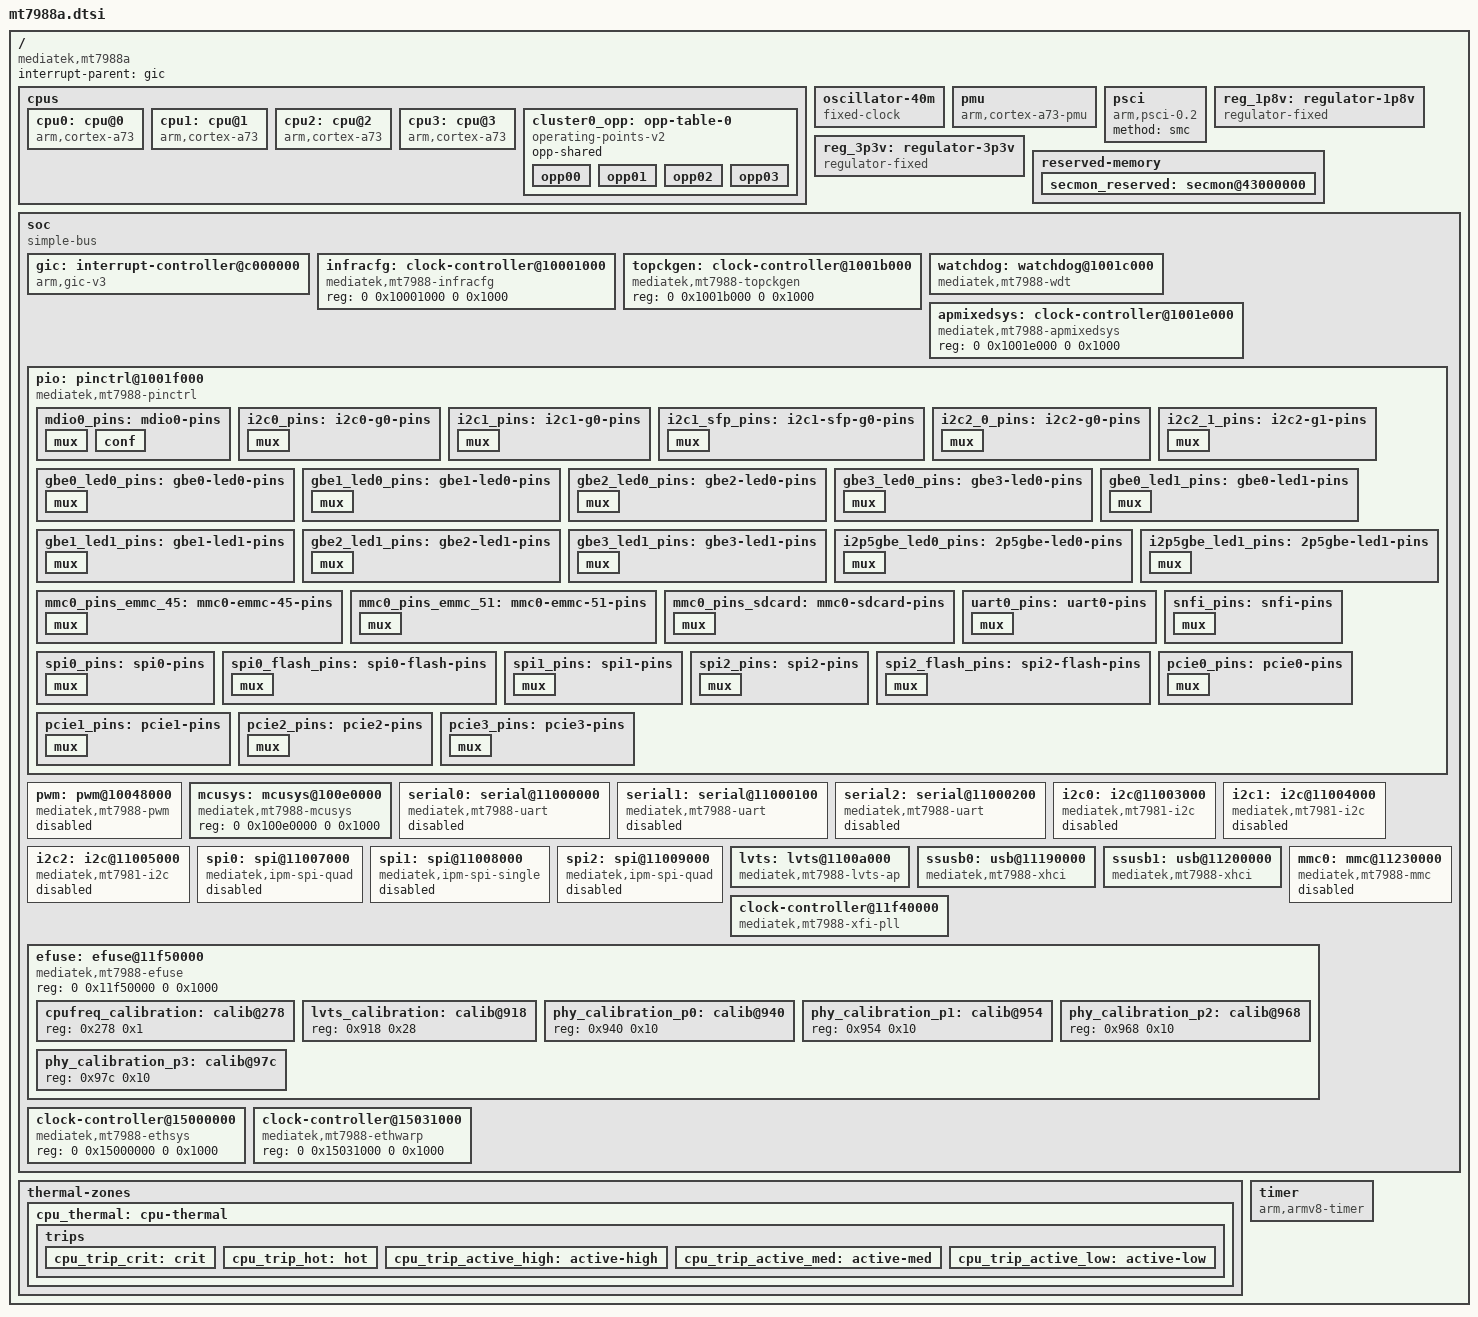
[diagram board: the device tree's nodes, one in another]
// SPDX-License-Identifier: GPL-2.0-only OR MIT

#include <dt-bindings/clock/mediatek,mt7988-clk.h>
#include <dt-bindings/interrupt-controller/arm-gic.h>
#include <dt-bindings/phy/phy.h>
#include <dt-bindings/pinctrl/mt65xx.h>
#include <dt-bindings/reset/mediatek,mt7988-resets.h>

/ {
	compatible = "mediatek,mt7988a";
	interrupt-parent = <&gic>;
	#address-cells = <2>;
	#size-cells = <2>;

	cpus {
		#address-cells = <1>;
		#size-cells = <0>;

		cpu0: cpu@0 {
			compatible = "arm,cortex-a73";
			reg = <0x0>;
			device_type = "cpu";
			enable-method = "psci";
			clocks = <&mcusys CLK_MCU_ARM_DIV_SEL>,
				 <&topckgen CLK_TOP_XTAL>;
			clock-names = "cpu", "intermediate";
			operating-points-v2 = <&cluster0_opp>;
		};

		cpu1: cpu@1 {
			compatible = "arm,cortex-a73";
			reg = <0x1>;
			device_type = "cpu";
			enable-method = "psci";
			clocks = <&mcusys CLK_MCU_ARM_DIV_SEL>,
				 <&topckgen CLK_TOP_XTAL>;
			clock-names = "cpu", "intermediate";
			operating-points-v2 = <&cluster0_opp>;
		};

		cpu2: cpu@2 {
			compatible = "arm,cortex-a73";
			reg = <0x2>;
			device_type = "cpu";
			enable-method = "psci";
			clocks = <&mcusys CLK_MCU_ARM_DIV_SEL>,
				 <&topckgen CLK_TOP_XTAL>;
			clock-names = "cpu", "intermediate";
			operating-points-v2 = <&cluster0_opp>;
		};

		cpu3: cpu@3 {
			compatible = "arm,cortex-a73";
			reg = <0x3>;
			device_type = "cpu";
			enable-method = "psci";
			clocks = <&mcusys CLK_MCU_ARM_DIV_SEL>,
				 <&topckgen CLK_TOP_XTAL>;
			clock-names = "cpu", "intermediate";
			operating-points-v2 = <&cluster0_opp>;
		};

		cluster0_opp: opp-table-0 {
			compatible = "operating-points-v2";
			opp-shared;
			opp00 {
				opp-hz = /bits/ 64 <800000000>;
				opp-microvolt = <850000>;
			};
			opp01 {
				opp-hz = /bits/ 64 <1100000000>;
				opp-microvolt = <850000>;
			};
			opp02 {
				opp-hz = /bits/ 64 <1500000000>;
				opp-microvolt = <850000>;
			};
			opp03 {
				opp-hz = /bits/ 64 <1800000000>;
				opp-microvolt = <900000>;
			};
		};
	};

	oscillator-40m {
		compatible = "fixed-clock";
		clock-frequency = <40000000>;
		#clock-cells = <0>;
		clock-output-names = "clkxtal";
	};

	pmu {
		compatible = "arm,cortex-a73-pmu";
		interrupt-parent = <&gic>;
		interrupts = <GIC_PPI 7 IRQ_TYPE_LEVEL_LOW>;
	};

	psci {
		compatible = "arm,psci-0.2";
		method = "smc";
	};

	reg_1p8v: regulator-1p8v {
		compatible = "regulator-fixed";
		regulator-name = "fixed-1.8V";
		regulator-min-microvolt = <1800000>;
		regulator-max-microvolt = <1800000>;
		regulator-boot-on;
		regulator-always-on;
	};

	reg_3p3v: regulator-3p3v {
		compatible = "regulator-fixed";
		regulator-name = "fixed-3.3V";
		regulator-min-microvolt = <3300000>;
		regulator-max-microvolt = <3300000>;
		regulator-boot-on;
		regulator-always-on;
	};

	reserved-memory {
		#address-cells = <2>;
		#size-cells = <2>;
		ranges;

		/* 320 KiB reserved for ARM Trusted Firmware (BL31 and BL32) */
		secmon_reserved: secmon@43000000 {
			reg = <0 0x43000000 0 0x50000>;
			no-map;
		};
	};

	soc {
		compatible = "simple-bus";
		ranges;
		#address-cells = <2>;
		#size-cells = <2>;

		gic: interrupt-controller@c000000 {
			compatible = "arm,gic-v3";
			reg = <0 0x0c000000 0 0x40000>,  /* GICD */
			      <0 0x0c080000 0 0x200000>, /* GICR */
			      <0 0x0c400000 0 0x2000>,   /* GICC */
			      <0 0x0c410000 0 0x1000>,   /* GICH */
			      <0 0x0c420000 0 0x2000>;   /* GICV */
			interrupt-parent = <&gic>;
			interrupts = <GIC_PPI 9 IRQ_TYPE_LEVEL_HIGH>;
			interrupt-controller;
			#interrupt-cells = <3>;
		};

		infracfg: clock-controller@10001000 {
			compatible = "mediatek,mt7988-infracfg", "syscon";
			reg = <0 0x10001000 0 0x1000>;
			#clock-cells = <1>;
			#reset-cells = <1>;
		};

		topckgen: clock-controller@1001b000 {
			compatible = "mediatek,mt7988-topckgen", "syscon";
			reg = <0 0x1001b000 0 0x1000>;
			#clock-cells = <1>;
		};

		watchdog: watchdog@1001c000 {
			compatible = "mediatek,mt7988-wdt";
			reg = <0 0x1001c000 0 0x1000>;
			interrupts = <GIC_SPI 110 IRQ_TYPE_LEVEL_HIGH>;
			#reset-cells = <1>;
		};

		apmixedsys: clock-controller@1001e000 {
			compatible = "mediatek,mt7988-apmixedsys";
			reg = <0 0x1001e000 0 0x1000>;
			#clock-cells = <1>;
		};

		pio: pinctrl@1001f000 {
			compatible = "mediatek,mt7988-pinctrl";
			reg = <0 0x1001f000 0 0x1000>,
			      <0 0x11c10000 0 0x1000>,
			      <0 0x11d00000 0 0x1000>,
			      <0 0x11d20000 0 0x1000>,
			      <0 0x11e00000 0 0x1000>,
			      <0 0x11f00000 0 0x1000>,
			      <0 0x1000b000 0 0x1000>;
			reg-names = "gpio", "iocfg_tr",
				    "iocfg_br", "iocfg_rb",
				    "iocfg_lb", "iocfg_tl", "eint";
			gpio-controller;
			#gpio-cells = <2>;
			gpio-ranges = <&pio 0 0 84>;
			interrupt-controller;
			interrupts = <GIC_SPI 225 IRQ_TYPE_LEVEL_HIGH>;
			interrupt-parent = <&gic>;
			#interrupt-cells = <2>;

			mdio0_pins: mdio0-pins {
				mux {
					function = "eth";
					groups = "mdc_mdio0";
				};

				conf {
					pins = "SMI_0_MDC", "SMI_0_MDIO";
					drive-strength = <MTK_DRIVE_8mA>;
				};
			};

			i2c0_pins: i2c0-g0-pins {
				mux {
					function = "i2c";
					groups = "i2c0_1";
				};
			};

			i2c1_pins: i2c1-g0-pins {
				mux {
					function = "i2c";
					groups = "i2c1_0";
				};
			};

			i2c1_sfp_pins: i2c1-sfp-g0-pins {
				mux {
					function = "i2c";
					groups = "i2c1_sfp";
				};
			};

			i2c2_0_pins: i2c2-g0-pins {
				mux {
					function = "i2c";
					groups = "i2c2_0";
				};
			};

			i2c2_1_pins: i2c2-g1-pins {
				mux {
					function = "i2c";
					groups = "i2c2_1";
				};
			};

			gbe0_led0_pins: gbe0-led0-pins {
				mux {
					function = "led";
					groups = "gbe0_led0";
				};
			};

			gbe1_led0_pins: gbe1-led0-pins {
				mux {
					function = "led";
					groups = "gbe1_led0";
				};
			};

			gbe2_led0_pins: gbe2-led0-pins {
				mux {
					function = "led";
					groups = "gbe2_led0";
				};
			};

			gbe3_led0_pins: gbe3-led0-pins {
				mux {
					function = "led";
					groups = "gbe3_led0";
				};
			};

			gbe0_led1_pins: gbe0-led1-pins {
				mux {
					function = "led";
					groups = "gbe0_led1";
				};
			};

			gbe1_led1_pins: gbe1-led1-pins {
				mux {
					function = "led";
					groups = "gbe1_led1";
				};
			};

			gbe2_led1_pins: gbe2-led1-pins {
				mux {
					function = "led";
					groups = "gbe2_led1";
				};
			};

			gbe3_led1_pins: gbe3-led1-pins {
				mux {
					function = "led";
					groups = "gbe3_led1";
				};
			};

			i2p5gbe_led0_pins: 2p5gbe-led0-pins {
				mux {
					function = "led";
					groups = "2p5gbe_led0";
				};
			};

			i2p5gbe_led1_pins: 2p5gbe-led1-pins {
				mux {
					function = "led";
					groups = "2p5gbe_led1";
				};
			};

			mmc0_pins_emmc_45: mmc0-emmc-45-pins {
				mux {
					function = "flash";
					groups = "emmc_45";
				};
			};

			mmc0_pins_emmc_51: mmc0-emmc-51-pins {
				mux {
					function = "flash";
					groups = "emmc_51";
				};
			};

			mmc0_pins_sdcard: mmc0-sdcard-pins {
				mux {
					function = "flash";
					groups = "sdcard";
				};
			};

			uart0_pins: uart0-pins {
				mux {
					function = "uart";
					groups =  "uart0";
				};
			};

			snfi_pins: snfi-pins {
				mux {
					function = "flash";
					groups = "snfi";
				};
			};

			spi0_pins: spi0-pins {
				mux {
					function = "spi";
					groups = "spi0";
				};
			};

			spi0_flash_pins: spi0-flash-pins {
				mux {
					function = "spi";
					groups = "spi0", "spi0_wp_hold";
				};
			};

			spi1_pins: spi1-pins {
				mux {
					function = "spi";
					groups = "spi1";
				};
			};

			spi2_pins: spi2-pins {
				mux {
					function = "spi";
					groups = "spi2";
				};
			};

			spi2_flash_pins: spi2-flash-pins {
				mux {
					function = "spi";
					groups = "spi2", "spi2_wp_hold";
				};
			};

			pcie0_pins: pcie0-pins {
				mux {
					function = "pcie";
					groups = "pcie_2l_0_pereset", "pcie_clk_req_n0_0",
						 "pcie_wake_n0_0";
				};
			};

			pcie1_pins: pcie1-pins {
				mux {
					function = "pcie";
					groups = "pcie_2l_1_pereset", "pcie_clk_req_n1",
						 "pcie_wake_n1_0";
				};
			};

			pcie2_pins: pcie2-pins {
				mux {
					function = "pcie";
					groups = "pcie_1l_0_pereset", "pcie_clk_req_n2_0",
						 "pcie_wake_n2_0";
				};
			};

			pcie3_pins: pcie3-pins {
				mux {
					function = "pcie";
					groups = "pcie_1l_1_pereset", "pcie_clk_req_n3",
						 "pcie_wake_n3_0";
				};
			};
		};

		pwm: pwm@10048000 {
			compatible = "mediatek,mt7988-pwm";
			reg = <0 0x10048000 0 0x1000>;
			clocks = <&infracfg CLK_INFRA_66M_PWM_BCK>,
				 <&infracfg CLK_INFRA_66M_PWM_HCK>,
				 <&infracfg CLK_INFRA_66M_PWM_CK1>,
				 <&infracfg CLK_INFRA_66M_PWM_CK2>,
				 <&infracfg CLK_INFRA_66M_PWM_CK3>,
				 <&infracfg CLK_INFRA_66M_PWM_CK4>,
				 <&infracfg CLK_INFRA_66M_PWM_CK5>,
				 <&infracfg CLK_INFRA_66M_PWM_CK6>,
				 <&infracfg CLK_INFRA_66M_PWM_CK7>,
				 <&infracfg CLK_INFRA_66M_PWM_CK8>;
			clock-names = "top", "main", "pwm1", "pwm2", "pwm3",
				      "pwm4", "pwm5", "pwm6", "pwm7", "pwm8";
			#pwm-cells = <2>;
			status = "disabled";
		};

		mcusys: mcusys@100e0000 {
			compatible = "mediatek,mt7988-mcusys", "syscon";
			reg = <0 0x100e0000 0 0x1000>;
			#clock-cells = <1>;
		};

		serial0: serial@11000000 {
			compatible = "mediatek,mt7988-uart", "mediatek,mt6577-uart";
			reg = <0 0x11000000 0 0x100>;
			interrupts = <GIC_SPI 123 IRQ_TYPE_LEVEL_HIGH>;
			interrupt-names = "uart", "wakeup";
			clocks = <&topckgen CLK_TOP_UART_SEL>,
				 <&infracfg CLK_INFRA_52M_UART0_CK>;
			clock-names = "baud", "bus";
			status = "disabled";
		};

		serial1: serial@11000100 {
			compatible = "mediatek,mt7988-uart", "mediatek,mt6577-uart";
			reg = <0 0x11000100 0 0x100>;
			interrupts = <GIC_SPI 124 IRQ_TYPE_LEVEL_HIGH>;
			interrupt-names = "uart", "wakeup";
			clocks = <&topckgen CLK_TOP_UART_SEL>,
				 <&infracfg CLK_INFRA_52M_UART1_CK>;
			clock-names = "baud", "bus";
			status = "disabled";
		};

		serial2: serial@11000200 {
			compatible = "mediatek,mt7988-uart", "mediatek,mt6577-uart";
			reg = <0 0x11000200 0 0x100>;
			interrupts = <GIC_SPI 125 IRQ_TYPE_LEVEL_HIGH>;
			interrupt-names = "uart", "wakeup";
			clocks = <&topckgen CLK_TOP_UART_SEL>,
				 <&infracfg CLK_INFRA_52M_UART2_CK>;
			clock-names = "baud", "bus";
			status = "disabled";
		};

		i2c0: i2c@11003000 {
			compatible = "mediatek,mt7981-i2c";
			reg = <0 0x11003000 0 0x1000>,
			      <0 0x10217080 0 0x80>;
			interrupts = <GIC_SPI 136 IRQ_TYPE_LEVEL_HIGH>;
			clocks = <&infracfg CLK_INFRA_I2C_BCK>,
				 <&infracfg CLK_INFRA_66M_AP_DMA_BCK>;
			clock-names = "main", "dma";
			#address-cells = <1>;
			#size-cells = <0>;
			status = "disabled";
		};

		i2c1: i2c@11004000 {
			compatible = "mediatek,mt7981-i2c";
			reg = <0 0x11004000 0 0x1000>,
			      <0 0x10217100 0 0x80>;
			interrupts = <GIC_SPI 144 IRQ_TYPE_LEVEL_HIGH>;
			clocks = <&infracfg CLK_INFRA_I2C_BCK>,
				 <&infracfg CLK_INFRA_66M_AP_DMA_BCK>;
			clock-names = "main", "dma";
			#address-cells = <1>;
			#size-cells = <0>;
			status = "disabled";
		};

		i2c2: i2c@11005000 {
			compatible = "mediatek,mt7981-i2c";
			reg = <0 0x11005000 0 0x1000>,
			      <0 0x10217180 0 0x80>;
			interrupts = <GIC_SPI 145 IRQ_TYPE_LEVEL_HIGH>;
			clocks = <&infracfg CLK_INFRA_I2C_BCK>,
				 <&infracfg CLK_INFRA_66M_AP_DMA_BCK>;
			clock-names = "main", "dma";
			#address-cells = <1>;
			#size-cells = <0>;
			status = "disabled";
		};

		spi0: spi@11007000 {
			compatible = "mediatek,ipm-spi-quad", "mediatek,spi-ipm";
			reg = <0 0x11007000 0 0x100>;
			interrupts = <GIC_SPI 140 IRQ_TYPE_LEVEL_HIGH>;
			clocks = <&topckgen CLK_TOP_MPLL_D2>,
				 <&topckgen CLK_TOP_SPI_SEL>,
				 <&infracfg CLK_INFRA_104M_SPI0>,
				 <&infracfg CLK_INFRA_66M_SPI0_HCK>;
			clock-names = "parent-clk", "sel-clk", "spi-clk",
				      "hclk";
			#address-cells = <1>;
			#size-cells = <0>;
			status = "disabled";
		};

		spi1: spi@11008000 {
			compatible = "mediatek,ipm-spi-single", "mediatek,spi-ipm";
			reg = <0 0x11008000 0 0x100>;
			interrupts = <GIC_SPI 141 IRQ_TYPE_LEVEL_HIGH>;
			clocks = <&topckgen CLK_TOP_MPLL_D2>,
				 <&topckgen CLK_TOP_SPI_SEL>,
				 <&infracfg CLK_INFRA_104M_SPI1>,
				 <&infracfg CLK_INFRA_66M_SPI1_HCK>;
			clock-names = "parent-clk", "sel-clk", "spi-clk",
				      "hclk";
			#address-cells = <1>;
			#size-cells = <0>;
			pinctrl-names = "default";
			pinctrl-0 = <&spi1_pins>;
			status = "disabled";
		};

		spi2: spi@11009000 {
			compatible = "mediatek,ipm-spi-quad", "mediatek,spi-ipm";
			reg = <0 0x11009000 0 0x100>;
			interrupts = <GIC_SPI 142 IRQ_TYPE_LEVEL_HIGH>;
			clocks = <&topckgen CLK_TOP_MPLL_D2>,
				 <&topckgen CLK_TOP_SPI_SEL>,
				 <&infracfg CLK_INFRA_104M_SPI2_BCK>,
				 <&infracfg CLK_INFRA_66M_SPI2_HCK>;
			clock-names = "parent-clk", "sel-clk", "spi-clk",
				      "hclk";
			#address-cells = <1>;
			#size-cells = <0>;
			status = "disabled";
		};

		lvts: lvts@1100a000 {
			compatible = "mediatek,mt7988-lvts-ap";
			#thermal-sensor-cells = <1>;
			reg = <0 0x1100a000 0 0x1000>;
			clocks = <&infracfg CLK_INFRA_26M_THERM_SYSTEM>;
			interrupts = <GIC_SPI 138 IRQ_TYPE_LEVEL_HIGH>;
			resets = <&infracfg MT7988_INFRA_RST1_THERM_CTRL_SWRST>;
			nvmem-cells = <&lvts_calibration>;
			nvmem-cell-names = "lvts-calib-data-1";
		};

		ssusb0: usb@11190000 {
			compatible = "mediatek,mt7988-xhci", "mediatek,mtk-xhci";
			reg = <0 0x11190000 0 0x2e00>,
			      <0 0x11193e00 0 0x0100>;
			reg-names = "mac", "ippc";
			interrupts = <GIC_SPI 173 IRQ_TYPE_LEVEL_HIGH>;
			clocks = <&infracfg CLK_INFRA_USB_SYS>,
				 <&infracfg CLK_INFRA_USB_REF>,
				 <&infracfg CLK_INFRA_66M_USB_HCK>,
				 <&infracfg CLK_INFRA_133M_USB_HCK>,
				 <&infracfg CLK_INFRA_USB_XHCI>;
			clock-names = "sys_ck", "ref_ck", "mcu_ck", "dma_ck", "xhci_ck";
		};

		ssusb1: usb@11200000 {
			compatible = "mediatek,mt7988-xhci", "mediatek,mtk-xhci";
			reg = <0 0x11200000 0 0x2e00>,
			      <0 0x11203e00 0 0x0100>;
			reg-names = "mac", "ippc";
			interrupts = <GIC_SPI 172 IRQ_TYPE_LEVEL_HIGH>;
			clocks = <&infracfg CLK_INFRA_USB_SYS_CK_P1>,
				 <&infracfg CLK_INFRA_USB_CK_P1>,
				 <&infracfg CLK_INFRA_66M_USB_HCK_CK_P1>,
				 <&infracfg CLK_INFRA_133M_USB_HCK_CK_P1>,
				 <&infracfg CLK_INFRA_USB_XHCI_CK_P1>;
			clock-names = "sys_ck", "ref_ck", "mcu_ck", "dma_ck", "xhci_ck";
		};

		mmc0: mmc@11230000 {
			compatible = "mediatek,mt7988-mmc", "mediatek,mt7986-mmc";
			reg = <0 0x11230000 0 0x1000>,
			      <0 0x11D60000 0 0x1000>;
			interrupts = <GIC_SPI 143 IRQ_TYPE_LEVEL_HIGH>;
			clocks = <&infracfg CLK_INFRA_MSDC400>,
				 <&infracfg CLK_INFRA_MSDC2_HCK>,
				 <&infracfg CLK_INFRA_66M_MSDC_0_HCK>,
				 <&infracfg CLK_INFRA_133M_MSDC_0_HCK>;
			assigned-clocks = <&topckgen CLK_TOP_EMMC_250M_SEL>,
					  <&topckgen CLK_TOP_EMMC_400M_SEL>;
			assigned-clock-parents = <&topckgen CLK_TOP_NET1PLL_D5_D2>,
						 <&apmixedsys CLK_APMIXED_MSDCPLL>;
			clock-names = "source",
				      "hclk",
				      "axi_cg",
				      "ahb_cg";
			#address-cells = <1>;
			#size-cells = <0>;
			status = "disabled";
		};

		clock-controller@11f40000 {
			compatible = "mediatek,mt7988-xfi-pll";
			reg = <0 0x11f40000 0 0x1000>;
			resets = <&watchdog 16>;
			#clock-cells = <1>;
		};

		efuse: efuse@11f50000 {
			compatible = "mediatek,mt7988-efuse", "mediatek,efuse";
			reg = <0 0x11f50000 0 0x1000>;
			#address-cells = <1>;
			#size-cells = <1>;

			cpufreq_calibration: calib@278 {
				reg = <0x278 0x1>;
			};
			lvts_calibration: calib@918 {
				reg = <0x918 0x28>;
			};
			phy_calibration_p0: calib@940 {
				reg = <0x940 0x10>;
			};
			phy_calibration_p1: calib@954 {
				reg = <0x954 0x10>;
			};
			phy_calibration_p2: calib@968 {
				reg = <0x968 0x10>;
			};
			phy_calibration_p3: calib@97c {
				reg = <0x97c 0x10>;
			};
		};

		clock-controller@15000000 {
			compatible = "mediatek,mt7988-ethsys", "syscon";
			reg = <0 0x15000000 0 0x1000>;
			#clock-cells = <1>;
			#reset-cells = <1>;
		};

		clock-controller@15031000 {
			compatible = "mediatek,mt7988-ethwarp";
			reg = <0 0x15031000 0 0x1000>;
			#clock-cells = <1>;
			#reset-cells = <1>;
		};
	};

	thermal-zones {
		cpu_thermal: cpu-thermal {
			polling-delay-passive = <1000>;
			polling-delay = <1000>;
			thermal-sensors = <&lvts 0>;
			trips {
				cpu_trip_crit: crit {
					temperature = <125000>;
					hysteresis = <2000>;
					type = "critical";
				};

				cpu_trip_hot: hot {
					temperature = <120000>;
					hysteresis = <2000>;
					type = "hot";
				};

				cpu_trip_active_high: active-high {
					temperature = <115000>;
					hysteresis = <2000>;
					type = "active";
				};

				cpu_trip_active_med: active-med {
					temperature = <85000>;
					hysteresis = <2000>;
					type = "active";
				};

				cpu_trip_active_low: active-low {
					temperature = <40000>;
					hysteresis = <2000>;
					type = "active";
				};
			};
		};
	};

	timer {
		compatible = "arm,armv8-timer";
		interrupt-parent = <&gic>;
		interrupts = <GIC_PPI 13 IRQ_TYPE_LEVEL_LOW>,
			     <GIC_PPI 14 IRQ_TYPE_LEVEL_LOW>,
			     <GIC_PPI 11 IRQ_TYPE_LEVEL_LOW>,
			     <GIC_PPI 10 IRQ_TYPE_LEVEL_LOW>;
	};
};
